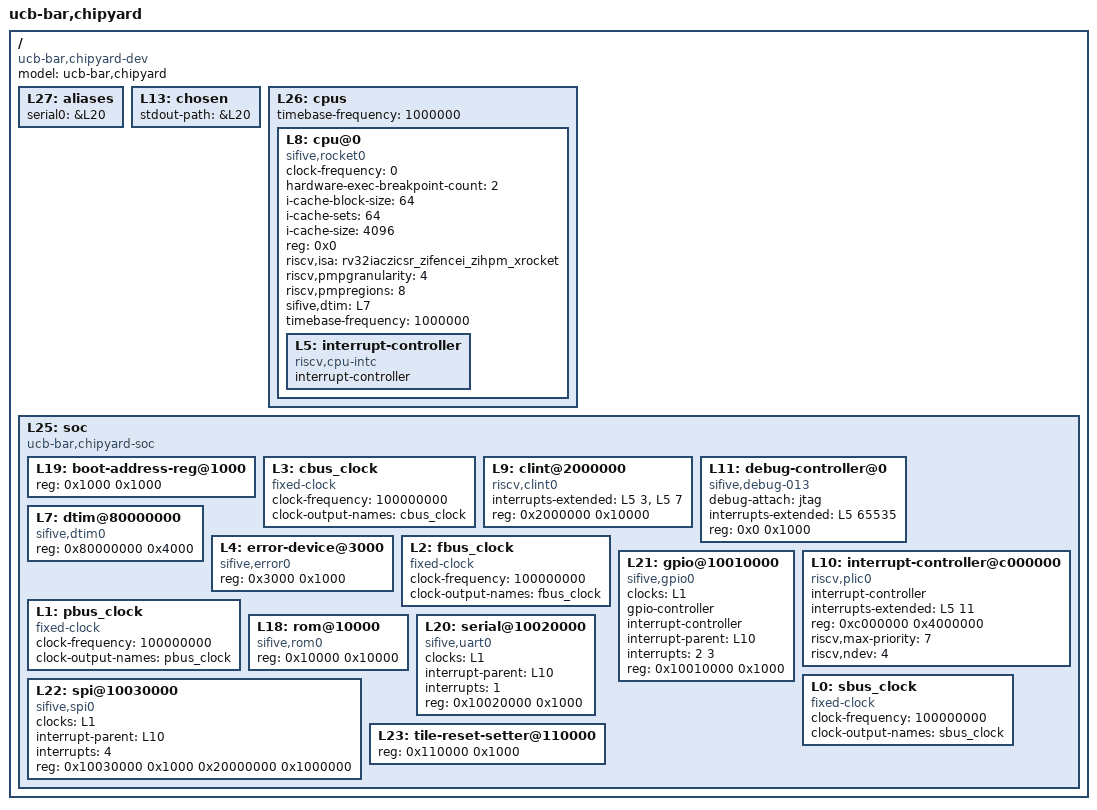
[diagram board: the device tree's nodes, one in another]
/dts-v1/;

/ {
	#address-cells = <1>;
	#size-cells = <1>;
	compatible = "ucb-bar,chipyard-dev";
	model = "ucb-bar,chipyard";
	L27: aliases {
		serial0 = &L20;
	};
	L13: chosen {
		stdout-path = &L20;
	};
	L26: cpus {
		#address-cells = <1>;
		#size-cells = <0>;
		timebase-frequency = <1000000>;
		L8: cpu@0 {
			clock-frequency = <0>;
			compatible = "sifive,rocket0", "riscv";
			device_type = "cpu";
			hardware-exec-breakpoint-count = <2>;
			i-cache-block-size = <64>;
			i-cache-sets = <64>;
			i-cache-size = <4096>;
			reg = <0x0>;
			riscv,isa = "rv32iaczicsr_zifencei_zihpm_xrocket";
			riscv,pmpgranularity = <4>;
			riscv,pmpregions = <8>;
			sifive,dtim = <&L7>;
			status = "okay";
			timebase-frequency = <1000000>;
			L5: interrupt-controller {
				#interrupt-cells = <1>;
				compatible = "riscv,cpu-intc";
				interrupt-controller;
			};
		};
	};
	L25: soc {
		#address-cells = <1>;
		#size-cells = <1>;
		compatible = "ucb-bar,chipyard-soc", "simple-bus";
		ranges;
		L19: boot-address-reg@1000 {
			reg = <0x1000 0x1000>;
			reg-names = "control";
		};
		L3: cbus_clock {
			#clock-cells = <0>;
			clock-frequency = <100000000>;
			clock-output-names = "cbus_clock";
			compatible = "fixed-clock";
		};
		L9: clint@2000000 {
			compatible = "riscv,clint0";
			interrupts-extended = <&L5 3 &L5 7>;
			reg = <0x2000000 0x10000>;
			reg-names = "control";
		};
		L11: debug-controller@0 {
			compatible = "sifive,debug-013", "riscv,debug-013";
			debug-attach = "jtag";
			interrupts-extended = <&L5 65535>;
			reg = <0x0 0x1000>;
			reg-names = "control";
		};
		L7: dtim@80000000 {
			compatible = "sifive,dtim0";
			reg = <0x80000000 0x4000>;
			reg-names = "mem";
		};
		L4: error-device@3000 {
			compatible = "sifive,error0";
			reg = <0x3000 0x1000>;
		};
		L2: fbus_clock {
			#clock-cells = <0>;
			clock-frequency = <100000000>;
			clock-output-names = "fbus_clock";
			compatible = "fixed-clock";
		};
		L21: gpio@10010000 {
			#gpio-cells = <2>;
			#interrupt-cells = <2>;
			clocks = <&L1>;
			compatible = "sifive,gpio0", "sifive,gpio1";
			gpio-controller;
			interrupt-controller;
			interrupt-parent = <&L10>;
			interrupts = <2 3>;
			reg = <0x10010000 0x1000>;
			reg-names = "control";
		};
		L10: interrupt-controller@c000000 {
			#interrupt-cells = <1>;
			compatible = "riscv,plic0";
			interrupt-controller;
			interrupts-extended = <&L5 11>;
			reg = <0xc000000 0x4000000>;
			reg-names = "control";
			riscv,max-priority = <7>;
			riscv,ndev = <4>;
		};
		L1: pbus_clock {
			#clock-cells = <0>;
			clock-frequency = <100000000>;
			clock-output-names = "pbus_clock";
			compatible = "fixed-clock";
		};
		L18: rom@10000 {
			compatible = "sifive,rom0";
			reg = <0x10000 0x10000>;
			reg-names = "mem";
		};
		L0: sbus_clock {
			#clock-cells = <0>;
			clock-frequency = <100000000>;
			clock-output-names = "sbus_clock";
			compatible = "fixed-clock";
		};
		L20: serial@10020000 {
			clocks = <&L1>;
			compatible = "sifive,uart0";
			interrupt-parent = <&L10>;
			interrupts = <1>;
			reg = <0x10020000 0x1000>;
			reg-names = "control";
		};
		L22: spi@10030000 {
			#address-cells = <1>;
			#size-cells = <0>;
			clocks = <&L1>;
			compatible = "sifive,spi0";
			interrupt-parent = <&L10>;
			interrupts = <4>;
			reg = <0x10030000 0x1000 0x20000000 0x1000000>;
			reg-names = "control", "mem";
		};
		L23: tile-reset-setter@110000 {
			reg = <0x110000 0x1000>;
			reg-names = "control";
		};
	};
};
